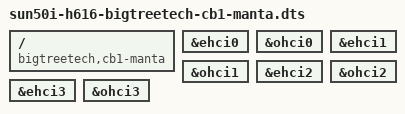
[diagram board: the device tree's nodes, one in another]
// SPDX-License-Identifier: (GPL-2.0+ or MIT)
/*
 * Copyright (C) 2022 Martin Botka <martin.botka@somainline.org>.
 */

/dts-v1/;

#include "sun50i-h616-bigtreetech-cb1.dtsi"

/ {
	compatible = "bigtreetech,cb1-manta", "bigtreetech,cb1", "allwinner,sun50i-h616";
};

&ehci0 {
	status = "okay";
};

&ohci0 {
	status = "okay";
};

&ehci1 {
	status = "okay";
};

&ohci1 {
	status = "okay";
};

&ehci2 {
	status = "okay";
};

&ohci2 {
	status = "okay";
};

&ehci3 {
	status = "okay";
};

&ohci3 {
	status = "okay";
};
